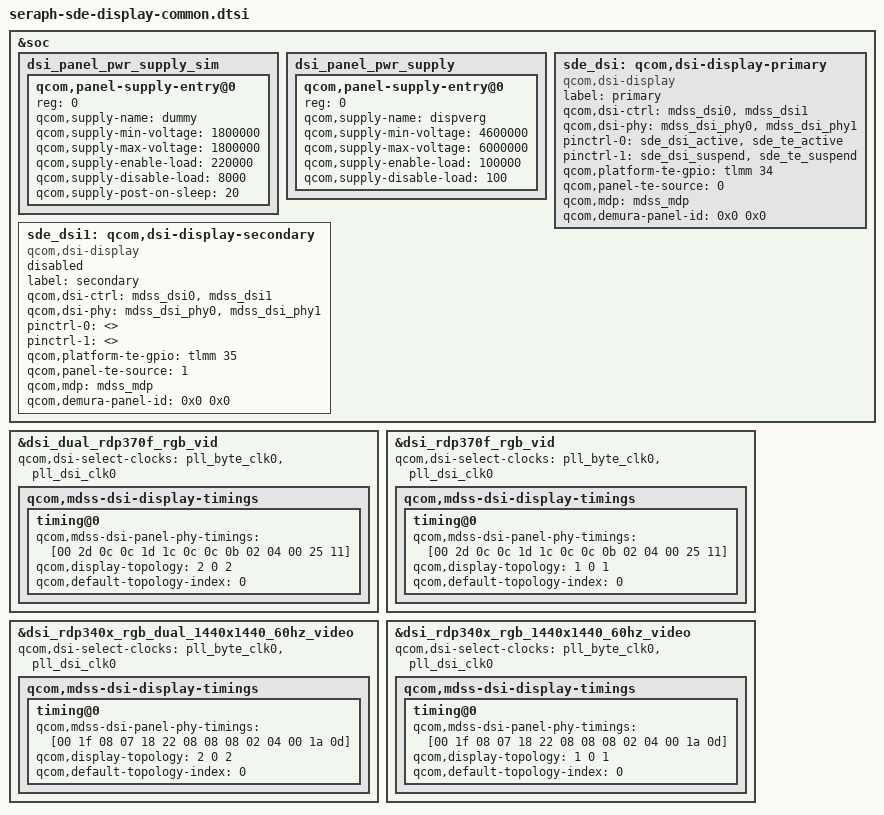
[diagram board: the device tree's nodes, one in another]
#include "dsi-panel-dual-rdp370f-rgb-video.dtsi"
#include "dsi-panel-rdp340x-rgb-dual-1440x1440-60hz-video.dtsi"
#include "dsi-panel-rdp370f-rgb-video.dtsi"
#include "dsi-panel-rdp340x-rgb-1440x1440-60hz-video.dtsi"

#include "seraph-sde-display-pinctrl.dtsi"

&soc {
	dsi_panel_pwr_supply_sim: dsi_panel_pwr_supply_sim {
		#address-cells = <1>;
		#size-cells = <0>;

		qcom,panel-supply-entry@0 {
			reg = <0>;
			qcom,supply-name = "dummy";
			qcom,supply-min-voltage = <1800000>;
			qcom,supply-max-voltage = <1800000>;
			qcom,supply-enable-load = <220000>;
			qcom,supply-disable-load = <8000>;
			qcom,supply-post-on-sleep = <20>;
		};
	};

	dsi_panel_pwr_supply: dsi_panel_pwr_supply {
		#address-cells = <1>;
		#size-cells = <0>;

		qcom,panel-supply-entry@0 {
			reg = <0>;
			qcom,supply-name = "dispverg";
			qcom,supply-min-voltage = <4600000>;
			qcom,supply-max-voltage = <6000000>;
			qcom,supply-enable-load = <100000>;
			qcom,supply-disable-load = <100>;
		};
	};

	sde_dsi: qcom,dsi-display-primary {
		compatible = "qcom,dsi-display";
		label = "primary";

		qcom,dsi-ctrl = <&mdss_dsi0 &mdss_dsi1>;
		qcom,dsi-phy = <&mdss_dsi_phy0 &mdss_dsi_phy1>;

		pinctrl-names = "panel_active", "panel_suspend";
		pinctrl-0 = <&sde_dsi_active &sde_te_active>;
		pinctrl-1 = <&sde_dsi_suspend &sde_te_suspend>;

		qcom,platform-te-gpio = <&tlmm 34 0>;
		qcom,panel-te-source = <0>;

		qcom,mdp = <&mdss_mdp>;
		qcom,demura-panel-id = <0x0 0x0>;
	};

	sde_dsi1: qcom,dsi-display-secondary {
		compatible = "qcom,dsi-display";
		label = "secondary";

		qcom,dsi-ctrl = <&mdss_dsi0 &mdss_dsi1>;
		qcom,dsi-phy = <&mdss_dsi_phy0 &mdss_dsi_phy1>;

		pinctrl-names = "panel_active", "panel_suspend";
		pinctrl-0 = <>;
		pinctrl-1 = <>;

		qcom,platform-te-gpio = <&tlmm 35 0>;
		qcom,panel-te-source = <1>;

		qcom,mdp = <&mdss_mdp>;
		qcom,demura-panel-id = <0x0 0x0>;

		status = "disabled";
	};
};

&dsi_dual_rdp370f_rgb_vid {
	qcom,dsi-select-clocks = "pll_byte_clk0", "pll_dsi_clk0";

	qcom,mdss-dsi-display-timings {
		timing@0 {
			qcom,mdss-dsi-panel-phy-timings = [00 2d 0c 0c 1d 1c 0c
				0c 0b 02 04 00 25 11];
			qcom,display-topology = <2 0 2>;
			qcom,default-topology-index = <0>;
		};
	};
};

&dsi_rdp370f_rgb_vid {
	qcom,dsi-select-clocks = "pll_byte_clk0", "pll_dsi_clk0";

	qcom,mdss-dsi-display-timings {
		timing@0 {
			qcom,mdss-dsi-panel-phy-timings = [00 2d 0c 0c 1d 1c 0c
				0c 0b 02 04 00 25 11];
			qcom,display-topology = <1 0 1>;
			qcom,default-topology-index = <0>;
		};
	};
};

&dsi_rdp340x_rgb_dual_1440x1440_60hz_video {
	qcom,dsi-select-clocks = "pll_byte_clk0", "pll_dsi_clk0";

	qcom,mdss-dsi-display-timings {
		timing@0 {
			qcom,mdss-dsi-panel-phy-timings = [00 1f 08 07 18 22 08
				08 08 02 04 00 1a 0d];
			qcom,display-topology = <2 0 2>;
			qcom,default-topology-index = <0>;
		};
	};
};

&dsi_rdp340x_rgb_1440x1440_60hz_video {
	qcom,dsi-select-clocks = "pll_byte_clk0", "pll_dsi_clk0";

	qcom,mdss-dsi-display-timings {
		timing@0 {
			qcom,mdss-dsi-panel-phy-timings = [00 1f 08 07 18 22 08
				08 08 02 04 00 1a 0d];
			qcom,display-topology = <1 0 1>;
			qcom,default-topology-index = <0>;
		};
	};
};
